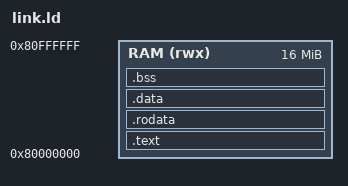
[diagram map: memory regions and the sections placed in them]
OUTPUT_ARCH(riscv)
ENTRY(_start)

MEMORY {
    RAM (rwx) : ORIGIN = 0x80000000, LENGTH = 16M
}

SECTIONS {
    .text : {
        *(.text.init)
        *(.text .text.*)
    } > RAM

    .rodata : {
        *(.rodata .rodata.*)
    } > RAM

    .data : {
        *(.data .data.*)
    } > RAM

    .bss (NOLOAD) : {
        _bss_start = .;
        *(.bss .bss.*)
        *(COMMON)
        . = ALIGN(4);
        _bss_end = .;
    } > RAM

    . = ALIGN(16);
    . = . + 8192;
    _stack_top = .;
}
